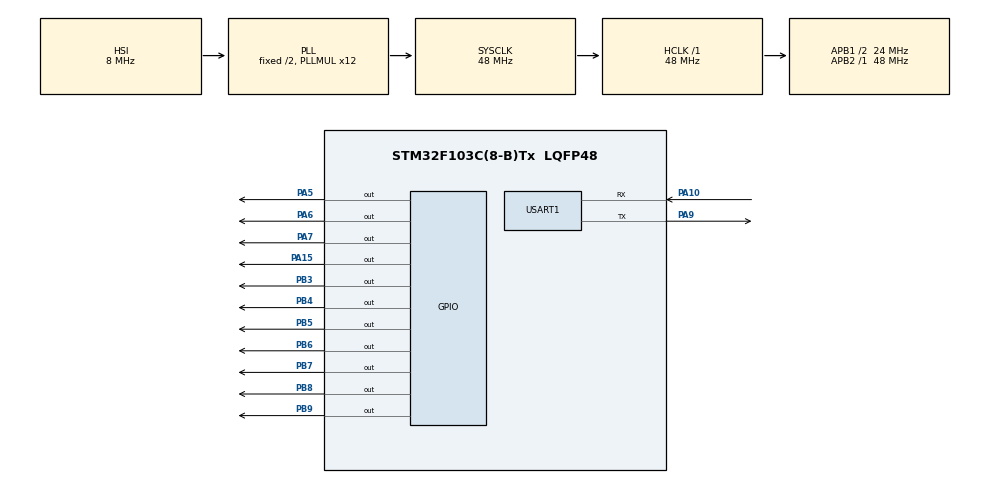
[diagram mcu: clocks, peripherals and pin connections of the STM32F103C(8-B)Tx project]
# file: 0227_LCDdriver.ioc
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Mcu.Family=STM32F1
Mcu.Name=STM32F103C(8-B)Tx
Mcu.Package=LQFP48
NVIC.PriorityGroup=NVIC_PRIORITYGROUP_4
PA10.Mode=Asynchronous
PA10.Signal=USART1_RX
PA13.Mode=Serial_Wire
PA13.Signal=SYS_JTMS-SWDIO
PA14.Mode=Serial_Wire
PA14.Signal=SYS_JTCK-SWCLK
PA15.GPIO_Speed=GPIO_SPEED_FREQ_HIGH
PA15.Signal=GPIO_Output
PA5.GPIO_Speed=GPIO_SPEED_FREQ_HIGH
PA5.Signal=GPIO_Output
PA6.GPIO_Speed=GPIO_SPEED_FREQ_HIGH
PA6.Signal=GPIO_Output
PA7.GPIO_Speed=GPIO_SPEED_FREQ_HIGH
PA7.Signal=GPIO_Output
PA9.Mode=Asynchronous
PA9.Signal=USART1_TX
PB3.GPIO_Speed=GPIO_SPEED_FREQ_HIGH
PB3.Signal=GPIO_Output
PB4.GPIO_Speed=GPIO_SPEED_FREQ_HIGH
PB4.Signal=GPIO_Output
PB5.GPIO_Speed=GPIO_SPEED_FREQ_HIGH
PB5.Signal=GPIO_Output
PB6.GPIO_Speed=GPIO_SPEED_FREQ_HIGH
PB6.Signal=GPIO_Output
PB7.GPIO_Speed=GPIO_SPEED_FREQ_HIGH
PB7.Signal=GPIO_Output
PB8.GPIO_Speed=GPIO_SPEED_FREQ_HIGH
PB8.Signal=GPIO_Output
PB9.GPIO_Speed=GPIO_SPEED_FREQ_HIGH
PB9.Signal=GPIO_Output
ProjectManager.HeapSize=0x200
ProjectManager.StackSize=0x400
ProjectManager.TargetToolchain=STM32CubeIDE
RCC.AHBFreq_Value=48000000
RCC.APB1CLKDivider=RCC_HCLK_DIV2
RCC.APB1Freq_Value=24000000
RCC.APB1TimFreq_Value=48000000
RCC.APB2Freq_Value=48000000
RCC.APB2TimFreq_Value=48000000
RCC.HCLKFreq_Value=48000000
RCC.PLLMUL=RCC_PLL_MUL12
RCC.SYSCLKFreq_VALUE=48000000
RCC.SYSCLKSource=RCC_SYSCLKSOURCE_PLLCLK
RCC.USBFreq_Value=48000000
USART1.VirtualMode=VM_ASYNC
board=custom

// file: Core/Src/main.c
/* USER CODE BEGIN Header */
/**
  ******************************************************************************
  * @file           : main.c
  * @brief          : Main program body
  ******************************************************************************
  * @attention
  *
  * Copyright (c) 2024 STMicroelectronics.
  * All rights reserved.
  *
  * This software is licensed under terms that can be found in the LICENSE file
  * in the root directory of this software component.
  * If no LICENSE file comes with this software, it is provided AS-IS.
  *
  ******************************************************************************
  */
/* USER CODE END Header */
#include "main.h"
#include "usart.h"
#include "gpio.h"
#include "lcd1602driver.h"

/* USER CODE BEGIN PV */
unsigned char content[5] = {0xCA,0xC2,0xC8,0xD0,0xB8};		//HATSUNE MIKU
/* USER CODE END PV */

void SystemClock_Config(void);

int main(void)
{

  /* MCU Configuration--------------------------------------------------------*/

  /* Reset of all peripherals, Initializes the Flash interface and the Systick. */
  HAL_Init();

  /* Configure the system clock */
  SystemClock_Config();

  /* Initialize all configured peripherals */
  MX_GPIO_Init();
  MX_USART1_UART_Init();
  /* USER CODE BEGIN 2 */
  LCD_AutoInit();
  HAL_Delay(5000);
  HAL_UART_Transmit(&huart1, (unsigned char*)"initialization succeed\n", 23, 0xffff);
  /* USER CODE END 2 */

  /* Infinite loop */
  while (1)
  {
	  LCD_Clear();
	  LCD_SetDDRAM(0x00);
	  for(int i=0; i < 5; i++)
	  {
	 	 LCD_WriteData(content[i]);
	 	 HAL_Delay(50);
	  }
	  HAL_Delay(2000);
  }
}

void SystemClock_Config(void)
{
  RCC_OscInitTypeDef RCC_OscInitStruct = {0};
  RCC_ClkInitTypeDef RCC_ClkInitStruct = {0};

  /** Initializes the RCC Oscillators according to the specified parameters
  * in the RCC_OscInitTypeDef structure.
  */
  RCC_OscInitStruct.OscillatorType = RCC_OSCILLATORTYPE_HSI;
  RCC_OscInitStruct.HSIState = RCC_HSI_ON;
  RCC_OscInitStruct.HSICalibrationValue = RCC_HSICALIBRATION_DEFAULT;
  RCC_OscInitStruct.PLL.PLLState = RCC_PLL_ON;
  RCC_OscInitStruct.PLL.PLLSource = RCC_PLLSOURCE_HSI_DIV2;
  RCC_OscInitStruct.PLL.PLLMUL = RCC_PLL_MUL12;
  if (HAL_RCC_OscConfig(&RCC_OscInitStruct) != HAL_OK)
  {
    Error_Handler();
  }

  /** Initializes the CPU, AHB and APB buses clocks
  */
  RCC_ClkInitStruct.ClockType = RCC_CLOCKTYPE_HCLK|RCC_CLOCKTYPE_SYSCLK
                              |RCC_CLOCKTYPE_PCLK1|RCC_CLOCKTYPE_PCLK2;
  RCC_ClkInitStruct.SYSCLKSource = RCC_SYSCLKSOURCE_PLLCLK;
  RCC_ClkInitStruct.AHBCLKDivider = RCC_SYSCLK_DIV1;
  RCC_ClkInitStruct.APB1CLKDivider = RCC_HCLK_DIV2;
  RCC_ClkInitStruct.APB2CLKDivider = RCC_HCLK_DIV1;

  if (HAL_RCC_ClockConfig(&RCC_ClkInitStruct, FLASH_LATENCY_1) != HAL_OK)
  {
    Error_Handler();
  }
}

void Error_Handler(void)
{
  __disable_irq();
  while (1)
  {
  }
}
